# TLE984x register map
Vendor: Infineon Technologies AG; File version: 1.6
CPU: CM0 r0p0, little endian, no MPU, no FPU, 2 interrupt priority bits
Registers are 32-bit, read-write, no defined reset value unless marked. A register's access mark holds for its fields unless they carry their own. Offsets are from the block's base; [hi:lo] are bit positions; {n}, {i} and the like mark numbered series; 'fields as' and 'values as' point back to an identical list.

## ADC1
Base 0x40004000
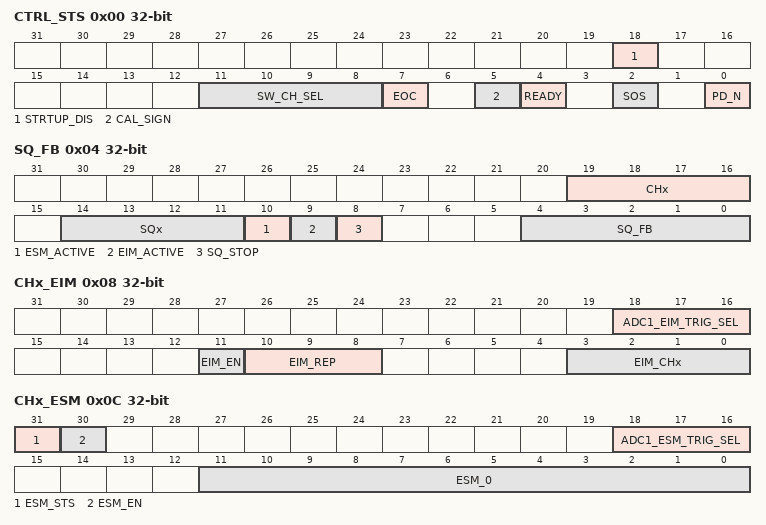
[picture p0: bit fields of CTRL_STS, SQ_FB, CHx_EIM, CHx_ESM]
0x00 CTRL_STS access per field — ADC1 Control and Status Register
  [18] STRTUP_DIS rw — DPP1 Startup Disable
    0=Startup Enable (DPP1 Startup enabled); 1=Startup Disable (DPP1 Startup disable)
  [11:8] SW_CH_SEL rw — Channel for software mode
    {v}=CH{v}_EN (Channel {v} enable) (v=0..12)
  [7] EOC ro — ADC1 End of Conversion (software mode)
    0=Pending (conversion still running); 1=Finished (conversion has finished)
  [5] CAL_SIGN ro — Output of Comparator to Steer Gain / Offset calibration
  [4] READY ro — HVADC Ready bit
    0=Not ready (Module in power down or in init phase); 1=Ready (set automatically 5 ADC clock cycles after module is enabled)
  [2] SOS rw — ADC1 Start of Sampling/Conversion (software mode)
    0=Disable (no conversion is started); 1=Enable (conversion is started)
  [0] PD_N rw — ADC1 Power Down Signal
    0=POWER DOWN (ADC1 is powered down); 1=ACTIVE (ADC1 is switched on)
0x04 SQ_FB ro — Sequencer Feedback Register
  [19:16] CHx — Current ADC1 Channel
    {v}=CH{v} (Channel {v} enable) (v=0..11)
  [14:11] SQx — Current Active ADC1 Sequence
    {v}=SQ{v} (Sequence {v} enable) (v=0..11)
  [10] ESM_ACTIVE — ADC1 ESM active
    0=not active (ESM not active); 1=active (ESM active)
  [9] EIM_ACTIVE — ADC1 EIM active
    0=not active (EIM not active); 1=active (EIM active)
  [8] SQ_STOP — ADC1 Sequencer Stop Signal for DPP
    0=DPP Running (Postprocessing Sequencer in running mode); 1=DPP Stopped (Postprocessing Sequencer stopped / Software Mode entered)
  [4:0] SQ_FB — Current Sequence that caused software mode
    {v}=SQ{v} (Sequence {v} enable) (v=0..11); 26=ESM; 28=SUSPEND_SW (SW Mode per Flag); 29=SUSPEND_DBG (Debug Suspend Mode)
0x08 CHx_EIM — Channel Setting Bits for Exceptional Interrupt Measurement
  [18:16] ADC1_EIM_TRIG_SEL — Trigger selection for exceptional interrupt measurement (EIM)
    0=NONE; 1=COUT63; 2=GPT12_T6OUT; 3=GPT12_T3OUT; 4=T2 (t2_adc_trigger); 5=T21 (t21_adc_trigger)
  [11] EIM_EN — Exceptional interrupt measurement (EIM) Trigger Event enable
    0=DISABLE (start of EIM disabled); 1=ENABLE (start of IEM enabled)
  [10:8] EIM_REP — Repeat count for exceptional interrupt measurement (EIM)
    {v}=Measurements (v=0..7)
  [3:0] EIM_CHx — Channel set for exceptional interrupt measurement (EIM)
    {v}=CH{v}_EN (Channel {v} enable) (v=0..11)
0x0C CHx_ESM — Channel Setting Bits for Exceptional Sequence Measurement
  [31] ESM_STS — Exceptional Sequence Measurement is finished
    0=not active (Exceptional Sequence Measurement not done); 1=done (Exceptional Sequence Measurement done)
  [30] ESM_EN — Enable for Exceptional Sequence Measurement Trigger Event
    0=Disable (start of ESM disabled); 1=Enable (start of ESM enabled)
  [18:16] ADC1_ESM_TRIG_SEL — Trigger selection for exceptional interrupt measurement (ESM)
    values as CHx_EIM.ADC1_EIM_TRIG_SEL
  [11:0] ESM_0 — Channel Sequence for Exceptional Sequence Measurement (ESM)
    1=CH0_EN (Channel 0 enable); 2=CH1_EN (Channel 1 enable); 4=CH2_EN (Channel 2 enable); 8=CH3_EN (Channel 3 enable); 16=CH4_EN (Channel 4 enable); 32=CH5_EN (Channel 5 enable); 64=CH6_EN (Channel 6 enable); 128=CH7_EN (Channel 7 enable); 0x100=CH8_EN (Channel 8 enable); 0x200=CH9_EN (Channel 9 enable); 0x400=CH10_EN (Channel 10 enable); 0x800=CH11_EN (Channel 11 enable)
0x10 MAX_TIME — Maximum Time for Software Mode
  [7:0] MAX_TIME — Maximum Time in Software Mode
    0=min (Software mode is immediately left); 255=max (Software mode is active for 12.75 us)
0x14 CTRL2 — Measurement Unit 1 Control Register 2
  [11:0] CAL_EN — Calibration Enable for Channels 0 to 11
    1=CH0_EN (Channel 0 calibration enable); 2=CH1_EN (Channel 1 calibration enable); 4=CH2_EN (Channel 2 calibration enable); 8=CH3_EN (Channel 3 calibration enable); 16=CH4_EN (Channel 4 calibration enable); 32=CH5_EN (Channel 5 calibration enable); 64=CH6_EN (Channel 6 calibration enable); 128=CH7_EN (Channel 7 calibration enable); 0x100=CH8_EN (Channel 8 calibration enable); 0x200=CH9_EN (Channel 9 calibration enable); 0x400=CH10_EN (Channel 10 calibration enable); 0x800=CH11_EN (Channel 11 calibration enable)
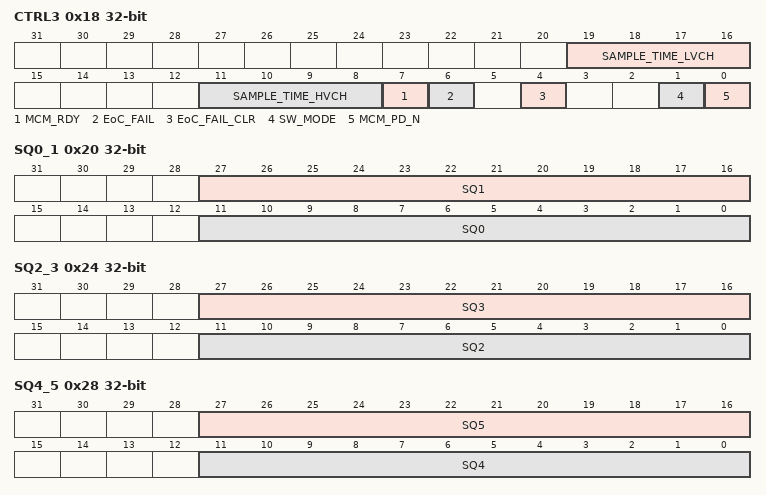
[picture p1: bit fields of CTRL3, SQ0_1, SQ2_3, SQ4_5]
0x18 CTRL3 access per field — Measurement Unit 1 Control Register 3
  [19:16] SAMPLE_TIME_LVCH rw — Sample time of ADC1
    0=MICLK4 (4 ADC1_CLK clock periods(default)); 1=MICLK6 (6 ADC1_CLK clock periods); 2=MICLK8 (8 ADC1_CLK clock periods); 3=MICLK10 (10 ADC1_CLK clock periods); 4=MICLK12 (12 ADC1_CLK clock periods); 5=MICLK14 (14 ADC1_CLK clock periods); 6=MICLK16 (16 ADC1_CLK clock periods); 7=MICLK18 (18 ADC1_CLK clock periods); 8=MICLK20 (20 ADC1_CLK clock periods); 9=MICLK22 (22 ADC1_CLK clock periods)
  [11:8] SAMPLE_TIME_HVCH rw — Sample time of ADC1
    0=MICLK4 (4 ADC1_CLK clock periods); 1=MICLK6 (6 ADC1_CLK clock periods); 2=MICLK8 (8 ADC1_CLK clock periods); 3=MICLK10 (10 ADC1_CLK clock periods); 4=MICLK12 (12 ADC1_CLK clock periods (default)); 5=MICLK14 (14 ADC1_CLK clock periods); 6=MICLK16 (16 ADC1_CLK clock periods); 7=MICLK18 (18 ADC1_CLK clock periods); 8=MICLK20 (20 ADC1_CLK clock periods); 9=MICLK22 (22 ADC1_CLK clock periods)
  [7] MCM_RDY ro — Ready Signal for MCM after Power On or Reset
    0=MCM Not Ready (Measurement Core Module in startup phase); 1=MCM Ready (Measurement Core Module start-up phase finished)
  [6] EoC_FAIL ro — Fail of ADC End of Conversion Signal
    0=ADC EoC available (End of Conversion Signal was sent properly by ADC); 1=ADC EoC not available (End of Conversion Signal was not sent properly by ADC)
  [4] EoC_FAIL_CLR wo — Fail of ADC End of Conversion Signal Clear
    0=ADC EoC Fail not clear (no clear of EoC_FAIL flag); 1=ADC EoC Fail clear (Clear of EoC_FAIL flag)
  [1] SW_MODE rw — SW Mode Enable
    0=Software Mode Disable (Sequencer running); 1=Software Mode Enabled (Sequencer stopped)
  [0] MCM_PD_N rw — Power Down Signal for MCM
    0=MCM Disabled (Measurement Core Module Disabled); 1=MCM Enabled (Measurement Core Module Enabled)
0x1C CTRL5 — Measurement Unit 1 Control Register 5
  [11:0] FILT_OUT_SEL_11_0 — Output Filter Selection for Channels 0 to 11
    0=ADC1 Unfiltered Data can be monitored in the corresponding FILT_OUTx Registers; 1=Channel 0 IIR Data enabled for FILT_OUT0 Register; 2=Channel 1 IIR Data enabled for FILT_OUT1 Register; 4=Channel 2 IIR Data enabled for FILT_OUT2 Register; 8=Channel 3 IIR Data enabled for FILT_OUT3 Register; 16=Channel 4 IIR Data enabled for FILT_OUT4 Register; 32=Channel 5 IIR Data enabled for FILT_OUT5 Register; 64=Channel 6 IIR Data enabled for FILT_OUT6 Register; 128=Channel 7 IIR Data enabled for FILT_OUT7 Register; 0x100=Channel 8 IIR Data enabled for FILT_OUT8 Register; 0x200=Channel 9 IIR Data enabled for FILT_OUT9 Register; 0x400=Channel 10 IIR Data enabled for FILT_OUT10 Register; 0x800=Channel 11 IIR Data enabled for FILT_OUT11 Register; 0xFFF=For Channels 11-0 IIR Data is enabled for FILT_OUTx Registers
0x20 SQ0_1 — Measurement Unit 1 Channel Enable Bits for Cycle 0-1
  [27:16] SQ1 — Sequence 1 channel enable
    values as CHx_ESM.ESM_0
  [11:0] SQ0 — Sequence 0 channel enable
    values as CHx_ESM.ESM_0
0x24 SQ2_3 — Measurement Unit 1 Channel Enable Bits for Cycle 2-3
  [27:16] SQ3 — Sequence 3 channel enable
    values as CHx_ESM.ESM_0
  [11:0] SQ2 — Sequence 2 channel enable
    values as CHx_ESM.ESM_0
0x28 SQ4_5 — Measurement Unit 1 Channel Enable Bits for Cycle 4-5
  [27:16] SQ5 — Sequence 5 channel enable
    values as CHx_ESM.ESM_0
  [11:0] SQ4 — Sequence 4 channel enable
    values as CHx_ESM.ESM_0
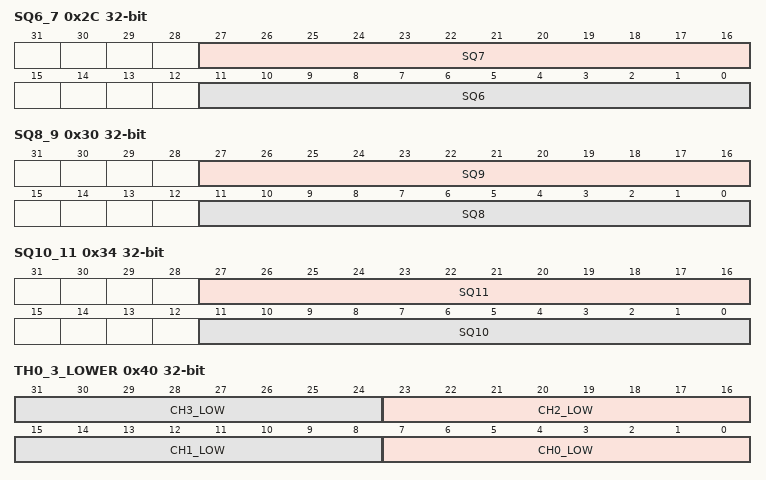
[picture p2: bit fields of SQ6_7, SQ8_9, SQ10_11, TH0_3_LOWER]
0x2C SQ6_7 — Measurement Unit 1 Channel Enable Bits for Cycle 6-7
  [27:16] SQ7 — Sequence 7 channel enable
    values as CHx_ESM.ESM_0
  [11:0] SQ6 — Sequence 6 channel enable
    values as CHx_ESM.ESM_0
0x30 SQ8_9 — Measurement Unit 1 Channel Enable Bits for Cycle 8-9
  [27:16] SQ9 — Sequence 9 channel enable
    values as CHx_ESM.ESM_0
  [11:0] SQ8 — Sequence 8 channel enable
    values as CHx_ESM.ESM_0
0x34 SQ10_11 — Measurement Unit 1 Channel Enable Bits for Cycle 10-11
  [27:16] SQ11 — Sequence 11 channel enable
    values as CHx_ESM.ESM_0
  [11:0] SQ10 — Sequence 10 channel enable
    values as CHx_ESM.ESM_0
0x38 CTRL4 — Measurement Unit 1 Control Register 4
  [3:0] MAX_CALTIME — Maximum ADC Calibration Time
    0=Sequence; 1=Sequences; 2=Sequences; 3=Sequences; 4=Sequence; {v}=Sequences (v=5..15)
0x40 TH0_3_LOWER — Lower Comparator Trigger Level Channel 0-3
  [all] fields
    0=Min. threshold value; 255=Max. threshold value
  [8n+7:8n] CH{n}_LOW (n=0..3) — Channel {n} lower trigger level
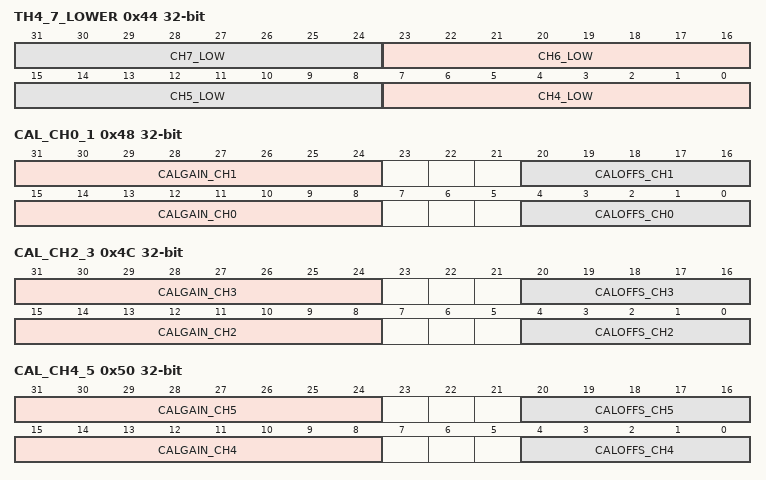
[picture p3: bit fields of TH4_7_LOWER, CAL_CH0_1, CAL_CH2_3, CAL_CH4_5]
0x44 TH4_7_LOWER — Lower Comparator Trigger Level Channel 4-7
  [all] fields
    0=Min. threshold value; 255=Max. threshold value
  [8n-25:8n-32] CH{n}_LOW (n=4..7) — Channel {n} lower trigger level
0x48 CAL_CH0_1 — Calibration for Channel 0 & 1
  [31:24] CALGAIN_CH1 — Gain Calibration for channel 1
  [20:16] CALOFFS_CH1 — Offset Calibration for channel 1
  [15:8] CALGAIN_CH0 — Gain Calibration for channel 0
  [4:0] CALOFFS_CH0 — Offset Calibration for channel 0
0x4C CAL_CH2_3 — Calibration for Channel 2 & 3
  [31:24] CALGAIN_CH3 — Gain Calibration for channel 3
  [20:16] CALOFFS_CH3 — Offset Calibration for channel 3
  [15:8] CALGAIN_CH2 — Gain Calibration for channel 2
  [4:0] CALOFFS_CH2 — Offset Calibration for channel 2
0x50 CAL_CH4_5 — Calibration for Channel 4 & 5
  [31:24] CALGAIN_CH5 — Gain Calibration for channel 5
  [20:16] CALOFFS_CH5 — Offset Calibration for channel 5
  [15:8] CALGAIN_CH4 — Gain Calibration for channel 4
  [4:0] CALOFFS_CH4 — Offset Calibration for channel 4
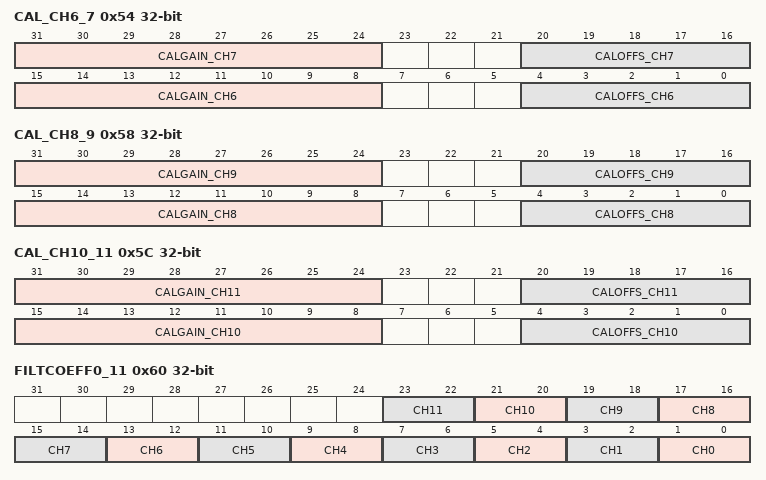
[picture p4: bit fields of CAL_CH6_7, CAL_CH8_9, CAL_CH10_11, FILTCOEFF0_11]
0x54 CAL_CH6_7 — Calibration for Channel 6 & 7
  [31:24] CALGAIN_CH7 — Gain Calibration for channel 7
  [20:16] CALOFFS_CH7 — Offset Calibration for channel 7
  [15:8] CALGAIN_CH6 — Gain Calibration for channel 6
  [4:0] CALOFFS_CH6 — Offset Calibration for channel 6
0x58 CAL_CH8_9 — Calibration for Channel 8 & 9
  [31:24] CALGAIN_CH9 — Gain Calibration for channel 9
  [20:16] CALOFFS_CH9 — Offset Calibration for channel 9
  [15:8] CALGAIN_CH8 — Gain Calibration for channel 8
  [4:0] CALOFFS_CH8 — Offset Calibration for channel 8
0x5C CAL_CH10_11 — Calibration for Channel 10 & 11
  [31:24] CALGAIN_CH11 — Gain Calibration for channel 11
  [20:16] CALOFFS_CH11 — Offset Calibration for channel 11
  [15:8] CALGAIN_CH10 — Gain Calibration for channel 10
  [4:0] CALOFFS_CH10 — Offset Calibration for channel 10
0x60 FILTCOEFF0_11 — Filter Coefficients Measurement Unit Channel 0-11
  [all] fields
    0=1/2 (weight of current sample); 1=1/4 (weight of current sample); 2=1/8 (weight of current sample); 3=1/16 (weight of current sample)
  [2n+1:2n] CH{n} (n=0..11) — Filter Coefficients ADC channel {n}
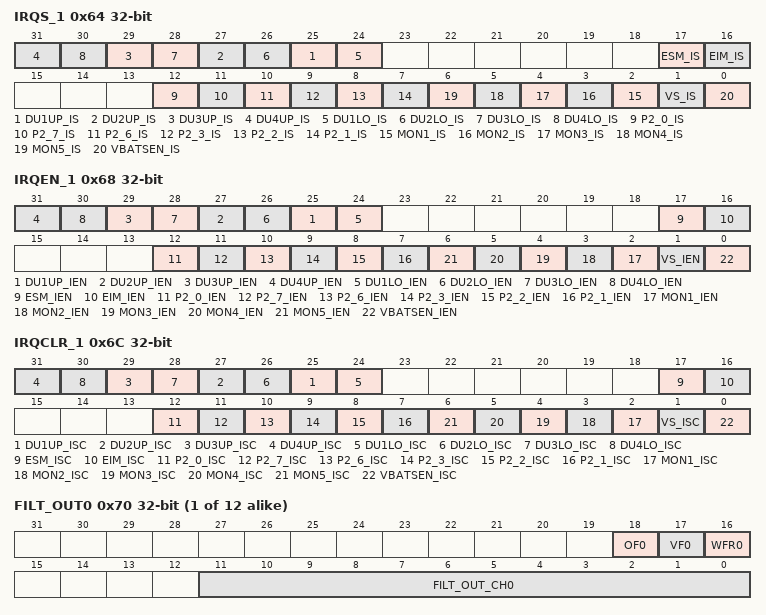
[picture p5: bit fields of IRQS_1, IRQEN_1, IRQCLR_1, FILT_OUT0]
0x64 IRQS_1 — ADC1 Interrupt Status 1 Register
  [2n+23] DU{n}UP_IS (n=1..4) — ADC1 Differential Unit {n} (DU{n}) upper Channel Interrupt Status
    0=INACTIVE (No DU upper Channel Interrupt has occurred); 1=ACTIVE (DU upper Channel Interrupt has occurred)
  [2n+22] DU{n}LO_IS (n=1..4) — ADC1 Differential Unit {n} (DU{n}) lower Channel Interrupt Status
    0=INACTIVE (No DU lower Channel Interrupt has occurred); 1=ACTIVE (DU lower Channel Interrupt has occurred)
  [17] ESM_IS — Exceptional Sequence Measurement (ESM) Status
    0=INACTIVE (No ESM has occurred); 1=ACTIVE (ESM occurred)
  [16] EIM_IS — Exceptional Interrupt Measurement (EIM) Status
    0=INACTIVE (No EIM occurred); 1=ACTIVE (EIM occurred)
  [12] P2_0_IS — ADC1 Channel 12 Interrupt Status
    0=INACTIVE (No Channel 12 Interrupt has occurred); 1=ACTIVE (Channel 12 Interrupt has occurred)
  [11] P2_7_IS — ADC1 Channel 11 Interrupt Status
    0=INACTIVE (No Channel 11 Interrupt has occurred); 1=ACTIVE (Channel 11 Interrupt has occurred)
  [10] P2_6_IS — ADC1 Channel 10 Interrupt Status
    0=INACTIVE (No Channel 10 Interrupt has occurred); 1=ACTIVE (Channel 10 Interrupt has occurred)
  [9] P2_3_IS — ADC1 Channel 9 Interrupt Status
    0=INACTIVE (No Channel 9 Interrupt has occurred); 1=ACTIVE (Channel 9 Interrupt has occurred)
  [8] P2_2_IS — ADC1 Channel 8 Interrupt Status
    0=INACTIVE (No Channel 8 Interrupt has occurred); 1=ACTIVE (Channel 8 Interrupt has occurred)
  [7] P2_1_IS — ADC1 Channel 7 Interrupt Status
    0=INACTIVE (No Channel 7 Interrupt has occurred); 1=ACTIVE (Channel 7 Interrupt has occurred)
  [n+1] MON{n}_IS (n=1..5) — ADC1 Channel {n+1} Interrupt Status
    0=INACTIVE (No Channel {n+1} Interrupt has occurred); 1=ACTIVE (Channel {n+1} Interrupt has occurred)
  [1] VS_IS — ADC1 Channel 0 Interrupt Status
    0=INACTIVE (No Channel 0 Interrupt has occurred); 1=ACTIVE (Channel 0 Interrupt has occurred)
  [0] VBATSEN_IS — ADC1 Channel 1 Interrupt Status
    0=INACTIVE (No Channel 1 Interrupt has occurred); 1=ACTIVE (Channel 1 Interrupt has occurred)
0x68 IRQEN_1 — ADC1 Interrupt Enable 1 Register
  [all] fields
    0=DISABLED (Interrupt disabled); 1=ENABLED (Interrupt enabled)
  [2n+23] DU{n}UP_IEN (n=1..4) — Differential Unit {n} upper Interrupt Enable
  [2n+22] DU{n}LO_IEN (n=1..4) — Differential Unit {n} lower Interrupt Enable
  [17] ESM_IEN — Exceptional Sequence Measurement (ESM) Interrupt Enable
  [16] EIM_IEN — Exceptional Interrupt Measurement (EIM) Interrupt Enable
  [12] P2_0_IEN — ADC1 Port 2.0 Interrupt Enable
  [11] P2_7_IEN — ADC1 Port 2.7 Interrupt Enable
  [10] P2_6_IEN — ADC1 Port 2.6 Interrupt Enable
  [9] P2_3_IEN — ADC1 Port 2.3 Interrupt Enable
  [8] P2_2_IEN — ADC1 Port 2.2 Interrupt Enable
  [7] P2_1_IEN — ADC1 Port 2.1 Interrupt Enable
  [n+1] MON{n}_IEN (n=1..5) — ADC1 MON {n} Interrupt Enable
  [1] VS_IEN — ADC1 VS Interrupt Enable
  [0] VBATSEN_IEN — ADC1 VBAT_SENSE Interrupt Enable
0x6C IRQCLR_1 wo — ADC1 Interrupt Status Clear 1 Register
  [2n+23] DU{n}UP_ISC (n=1..4) — Differential Unit {n} lower Interrupt Status Clear
    0=INACTIVE (interrupt status is not cleared); 1=ACTIVE (interrupt status is cleared)
  [2n+22] DU{n}LO_ISC (n=1..4) — Differential Unit {n} lower Interrupt Status Clear
    values as DU1UP_ISC
  [17] ESM_ISC — Exceptional Sequence Measurement (ESM) Status Clear
    0=INACTIVE (No ESM has cleared); 1=ACTIVE (ESM cleared)
  [16] EIM_ISC — Exceptional Interrupt Measurement (EIM) Status Clear
    0=INACTIVE (No EIM cleared); 1=ACTIVE (EIM cleared)
  [12] P2_0_ISC — ADC1 Port 2.0 Interrupt Status Clear
    values as DU1UP_ISC
  [11] P2_7_ISC — ADC1 Port 2.7 Interrupt Status Clear
    values as DU1UP_ISC
  [10] P2_6_ISC — ADC1 Port 2.6 Interrupt Status Clear
    values as DU1UP_ISC
  [9] P2_3_ISC — ADC1 Port 2.3 Interrupt Status Clear
    values as DU1UP_ISC
  [8] P2_2_ISC — ADC1 Port 2.2 Interrupt Status Clear
    values as DU1UP_ISC
  [7] P2_1_ISC — ADC1 Port 2.1 Interrupt Status Clear
    values as DU1UP_ISC
  [n+1] MON{n}_ISC (n=1..5) — ADC1 MON {n} Interrupt Status Clear
    values as DU1UP_ISC
  [1] VS_ISC — ADC1 VS Interrupt Status Clear
    values as DU1UP_ISC
  [0] VBATSEN_ISC — ADC1 VBAT_SENSE Interrupt Status Clear
    values as DU1UP_ISC
{0x70+4i} FILT_OUT{i} access per field (i=0..11) — ADC1 or Filter Output Channel {i}
  [18] OF{i} ro — Overrun Flag
    0=NO OVERRUN (Result register not overwritten); 1=OVERRUN (Result register overwritten)
  [17] VF{i} ro — Valid Flag
    0=NOT VALID (No new valid data available); 1=VALID (Result register contains valid data and has not yet been read)
  [16] WFR{i} rw — Wait for Read Mode
    0=DISABLE (overwrite mode); 1=ENABLE (wait for read mode enabled)
  [11:0] FILT_OUT_CH{i} ro — ADC or filter output value channel {i}
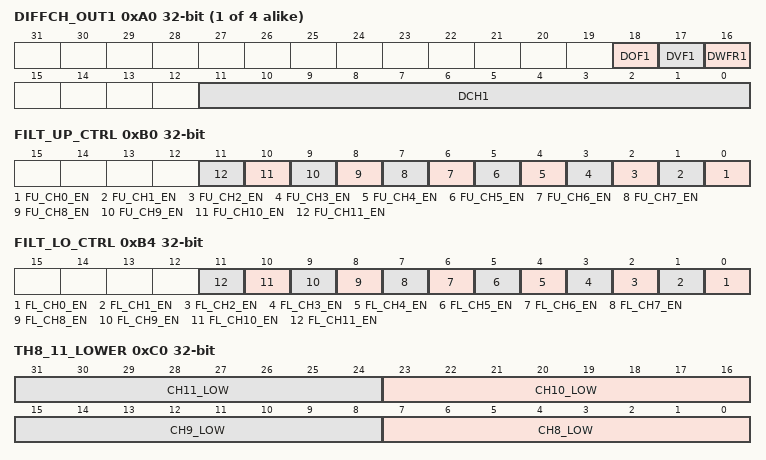
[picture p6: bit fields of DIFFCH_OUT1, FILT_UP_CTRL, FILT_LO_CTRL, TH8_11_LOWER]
{0x9C+4i} DIFFCH_OUT{i} access per field (i=1..4) — ADC1 Differential Channel Output {i}
  [18] DOF{i} ro — Overrun Flag
    values as FILT_OUT0.OF{i}
  [17] DVF{i} ro — Valid Flag
    values as FILT_OUT0.VF{i}
  [16] DWFR{i} rw — Wait for Read Mode
    values as FILT_OUT0.WFR{i}
  [11:0] DCH{i} ro — ADC differential output value {i}
0xB0 FILT_UP_CTRL — Upper Threshold Filter Enable
  [all] fields
    0=disable; 1=enable
  [n] FU_CH{n}_EN (n=0..11) — Upper threshold IIR filter enable Channel {n}
0xB4 FILT_LO_CTRL — Lower Threshold Filter Enable
  [all] fields
    0=disable; 1=enable
  [n] FL_CH{n}_EN (n=0..11) — Lower threshold IIR filter enable Channel {n}
0xC0 TH8_11_LOWER — Lower Comparator Trigger Level Channel 8-11
  [all] fields
    0=Min. threshold value; 255=Max. threshold value
  [8n-57:8n-64] CH{n}_LOW (n=8..11) — Channel {n} lower trigger level
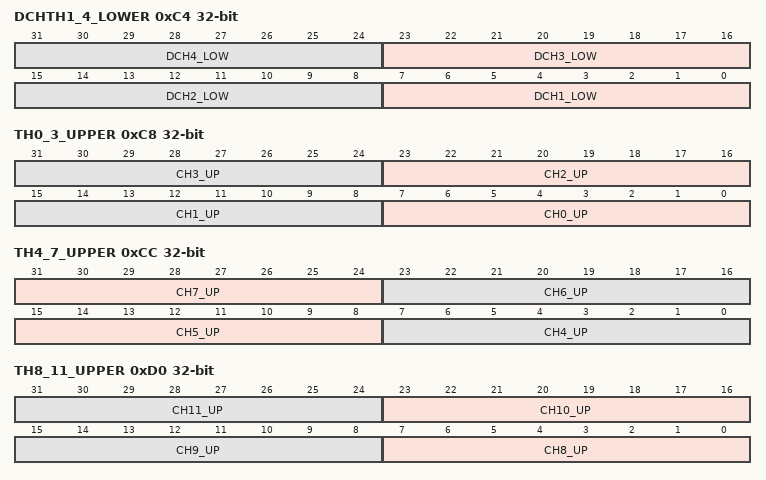
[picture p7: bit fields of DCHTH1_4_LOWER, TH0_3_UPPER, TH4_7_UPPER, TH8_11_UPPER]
0xC4 DCHTH1_4_LOWER — Lower Comparator Trigger Level Differential Channel 1-4
  [all] fields
    0=Min. threshold value; 255=Max. threshold value
  [8n-1:8n-8] DCH{n}_LOW (n=1..4) — Differential Channel {n} lower trigger level
0xC8 TH0_3_UPPER — Upper Comparator Trigger Level Channel 0-3
  [all] fields
    0=min. threshold value = 0; 255=max. threshold value = 255
  [8n+7:8n] CH{n}_UP (n=0..3) — Channel {n} upper trigger level
0xCC TH4_7_UPPER — Upper Comparator Trigger Level Channel 4-7
  [all] fields
    0=min. threshold value = 0; 255=max. threshold value = 255
  [31:24] CH7_UP — Channel 7 upper trigger level
  [23:16] CH6_UP — Channel 6upper trigger level
  [15:8] CH5_UP — Channel 5 upper trigger level
  [7:0] CH4_UP — Channel 4 upper trigger level
0xD0 TH8_11_UPPER — Upper Comparator Trigger Level Channel 8-11
  [all] fields
    0=min. threshold value = 0; 255=max. threshold value = 255
  [8n-57:8n-64] CH{n}_UP (n=8..11) — Channel {n} upper trigger level
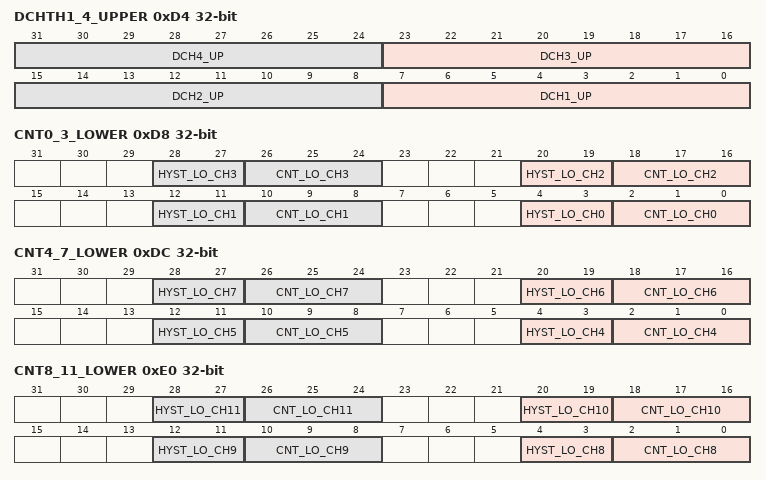
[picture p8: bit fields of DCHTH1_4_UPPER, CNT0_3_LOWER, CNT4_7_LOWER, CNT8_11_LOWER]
0xD4 DCHTH1_4_UPPER — Upper Comparator Trigger Level Differential Channel 1-4
  [all] fields
    0=min. threshold value = 0; 255=max. threshold value = 255
  [8n-1:8n-8] DCH{n}_UP (n=1..4) — Differential Channel {n} upper trigger level
0xD8 CNT0_3_LOWER — Lower Counter Trigger Level Channel 0-3
  [8n+4:8n+3] HYST_LO_CH{n} (n=0..3) — Channel {n} lower hysteresis
    0=HYSTOFF (hysteresis switched off); 1=HYST4 (hysteresis = 4); 2=HYST8 (hysteresis = 8); 3=HYST16 (hysteresis = 16)
  [8n+2:8n] CNT_LO_CH{n} (n=0..3) — Lower timer trigger threshold channel {n}
    0=1 measurement; 1=2 measurements; 2=4 measurements; 3=8 measurements; 4=16 measurements; 5=32 measurements; 6=63 measurements; 7=63 measurements
0xDC CNT4_7_LOWER — Lower Counter Trigger Level Channel 4-7
  [8n-28:8n-29] HYST_LO_CH{n} (n=4..7) — Channel {n} lower hysteresis
    values as CNT0_3_LOWER.HYST_LO_CH0
  [8n-30:8n-32] CNT_LO_CH{n} (n=4..7) — Lower timer trigger threshold channel {n}
    values as CNT0_3_LOWER.CNT_LO_CH0
0xE0 CNT8_11_LOWER — Lower Counter Trigger Level Channel 8-11
  [8n-60:8n-61] HYST_LO_CH{n} (n=8..11) — Channel {n} lower hysteresis
    values as CNT0_3_LOWER.HYST_LO_CH0
  [8n-62:8n-64] CNT_LO_CH{n} (n=8..11) — Lower timer trigger threshold channel {n}
    values as CNT0_3_LOWER.CNT_LO_CH0
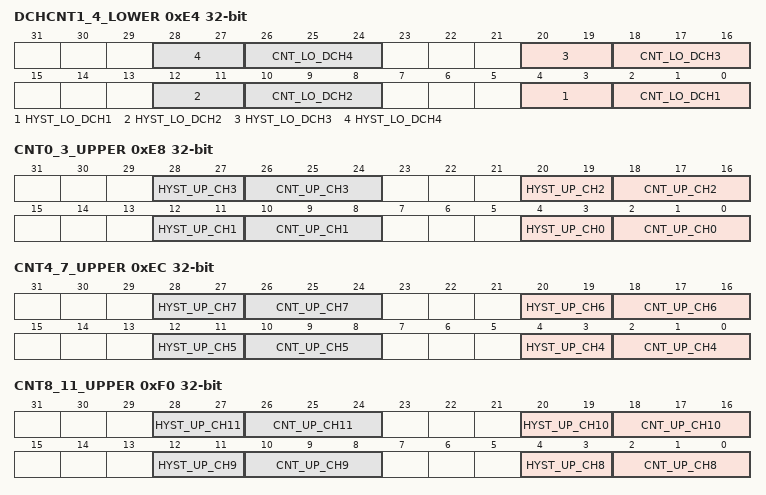
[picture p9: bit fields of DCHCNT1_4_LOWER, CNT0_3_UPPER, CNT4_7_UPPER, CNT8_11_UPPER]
0xE4 DCHCNT1_4_LOWER — Lower Counter Trigger Level Differential Channel 1-4
  [8n-4:8n-5] HYST_LO_DCH{n} (n=1..4) — Differential Channel {n} lower hysteresis
    values as CNT0_3_LOWER.HYST_LO_CH0
  [8n-6:8n-8] CNT_LO_DCH{n} (n=1..4) — Lower timer trigger threshold differential channel {n}
    values as CNT0_3_LOWER.CNT_LO_CH0
0xE8 CNT0_3_UPPER — Upper Counter Trigger Level Channel 0-3
  [8n+4:8n+3] HYST_UP_CH{n} (n=0..3) — Channel {n} upper hysteresis
    values as CNT0_3_LOWER.HYST_LO_CH0
  [8n+2:8n] CNT_UP_CH{n} (n=0..3) — Upper timer trigger threshold channel {n}
    values as CNT0_3_LOWER.CNT_LO_CH0
0xEC CNT4_7_UPPER — Upper Counter Trigger Level Channel 4-7
  [8n-28:8n-29] HYST_UP_CH{n} (n=4..7) — Channel {n} upper hysteresis
    values as CNT0_3_LOWER.HYST_LO_CH0
  [8n-30:8n-32] CNT_UP_CH{n} (n=4..7) — Upper timer trigger threshold channel {n}
    values as CNT0_3_LOWER.CNT_LO_CH0
0xF0 CNT8_11_UPPER — Upper Counter Trigger Level Channel 8-11
  [8n-60:8n-61] HYST_UP_CH{n} (n=8..11) — Channel {n} upper hysteresis
    values as CNT0_3_LOWER.HYST_LO_CH0
  [8n-62:8n-64] CNT_UP_CH{n} (n=8..11) — Upper timer trigger threshold channel {n}
    values as CNT0_3_LOWER.CNT_LO_CH0
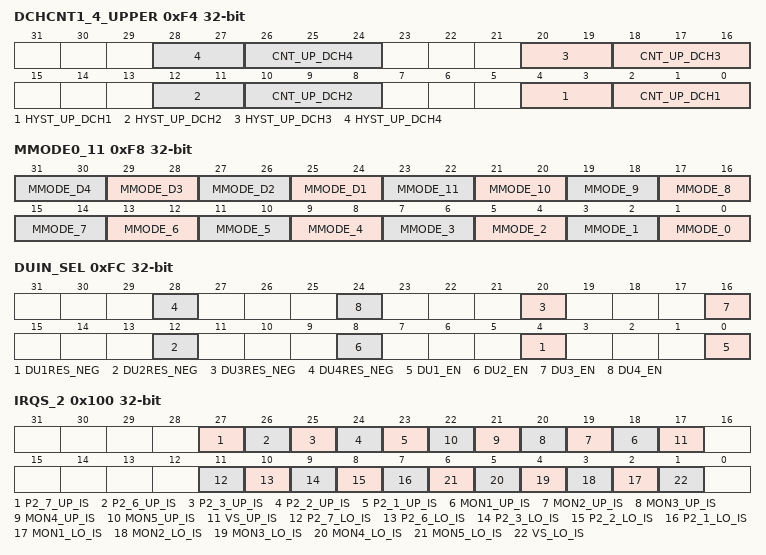
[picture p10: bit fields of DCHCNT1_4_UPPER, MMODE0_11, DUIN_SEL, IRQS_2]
0xF4 DCHCNT1_4_UPPER — Upper Counter Trigger Level Differential Channel 1-4
  [8n-4:8n-5] HYST_UP_DCH{n} (n=1..4) — Differential Channel {n} upper hysteresis
    values as CNT0_3_LOWER.HYST_LO_CH0
  [8n-6:8n-8] CNT_UP_DCH{n} (n=1..4) — Upper timer trigger threshold differential channel {n}
    0=1 measurement; 1=2 measurements; 2=4 measurements; 3=8 measurements; {v}=15 measurements (v=4..7)
0xF8 MMODE0_11 — Overvoltage Measurement Mode of Ch 0-11
  [all] fields
    0=MMODE0 (upper & lower voltage/limit measurement); 1=MMODEUV (undervoltage/-limit measurement); 2=MMODEOV (overvoltage/-limit measurement)
  [2n+23:2n+22] MMODE_D{n} (n=1..4) — Measurement mode Differential Channel {n}
  [2n+1:2n] MMODE_{n} (n=0..11) — Measurement mode Channel {n}
0xFC DUIN_SEL access per field — Measurement Unit 1 - Differential Unit Input Selection Register
  [8n-4] DU{n}RES_NEG ro (n=1..4) — Differential Unit {n} result negative
    0=DU{n} Result positive (Differential Unit {n} result positive after calculation); 1=DU{n} Result negative (Differential Unit {n} result negative after calculation)
  [8n-8] DU{n}_EN rw (n=1..4) — Differential Unit {n} enable
    0=DU{n} disable (Differential Unit {n} is disabled); 1=DU{n} enable (Differential Unit {n} is enabled)
0x100 IRQS_2 — ADC1 Interrupt Status 2 Register
  [all] fields
    0=INACTIVE (no interrupt has occurred); 1=ACTIVE (interrupt has occurred)
  [27] P2_7_UP_IS — ADC1 Port 2.7 Upper Threshold Interrupt Status
  [26] P2_6_UP_IS — ADC1 Port 2.6 Upper Threshold Interrupt Status
  [25] P2_3_UP_IS — ADC1 Port 2.3 Upper Threshold Interrupt Status
  [24] P2_2_UP_IS — ADC1 Port 2.2 Upper Threshold Interrupt Status
  [23] P2_1_UP_IS — ADC1 Port 2.1 Upper Threshold Interrupt Status
  [n+17] MON{n}_UP_IS (n=1..5) — ADC1 MON {n} Upper Threshold Interrupt Status
  [17] VS_UP_IS — ADC1 VS Upper Threshold Interrupt Status
  [11] P2_7_LO_IS — ADC1 Port 2.7 Lower Threshold Interrupt Status
  [10] P2_6_LO_IS — ADC1 Port 2.6 Lower Threshold Interrupt Status
  [9] P2_3_LO_IS — ADC1 Port 2.3 Lower Threshold Interrupt Status
  [8] P2_2_LO_IS — ADC1 Port 2.2 Lower Threshold Interrupt Status
  [7] P2_1_LO_IS — ADC1 Port 2.1 Lower Threshold Interrupt Status
  [n+1] MON{n}_LO_IS (n=1..5) — ADC1 MON {n} Lower Threshold Interrupt Status
  [1] VS_LO_IS — ADC1 VS Lower Threshold Interrupt Status
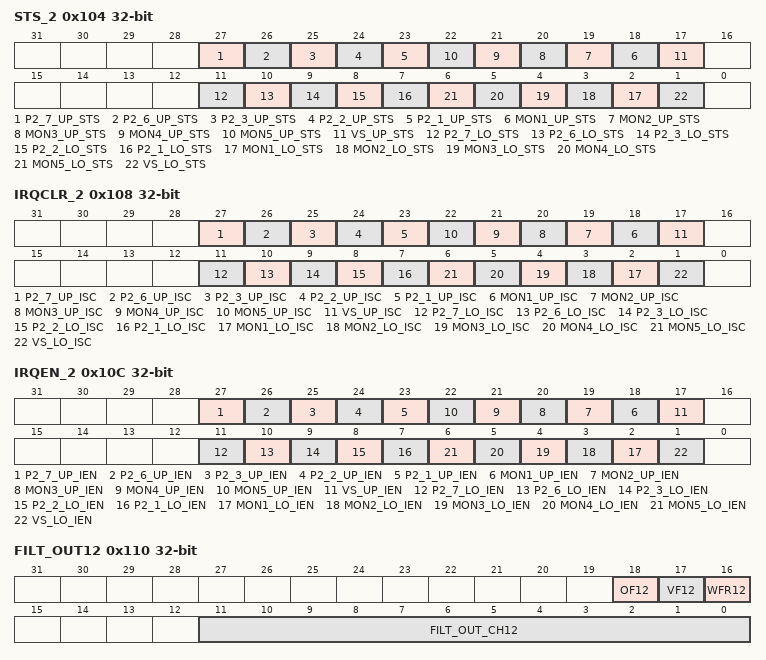
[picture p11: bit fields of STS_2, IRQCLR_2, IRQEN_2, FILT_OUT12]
0x104 STS_2 ro — ADC1 Status 2 Register
  [all] fields
    0=Below limit (Status below upper threshold); 1=Above limit (Upper threshold exceeded)
  [27] P2_7_UP_STS — ADC1 Port 2.7 Upper Threshold Status
  [26] P2_6_UP_STS — ADC1 Port 2.6 Upper Threshold Status
  [25] P2_3_UP_STS — ADC1 Port 2.3 Upper Threshold Status
  [24] P2_2_UP_STS — ADC1 Port 2.2 Upper Threshold Status
  [23] P2_1_UP_STS — ADC1 Port 2.1 Upper Threshold Status
  [n+17] MON{n}_UP_STS (n=1..5) — ADC1 MON {n} Upper Threshold Status
  [17] VS_UP_STS — ADC1 VS Upper Threshold Status
  [11] P2_7_LO_STS — ADC1 Port 2.7 Lower Threshold Status
  [10] P2_6_LO_STS — ADC1 Port 2.6 Lower Threshold Status
  [9] P2_3_LO_STS — ADC1 Port 2.3 Lower Threshold Status
  [8] P2_2_LO_STS — ADC1 Port 2.2 Lower Threshold Status
  [7] P2_1_LO_STS — ADC1 Port 2.1 Lower Threshold Status
  [n+1] MON{n}_LO_STS (n=1..5) — ADC1 MON {n} Lower Threshold Status
  [1] VS_LO_STS — ADC1 VS Lower Threshold Status
0x108 IRQCLR_2 wo — ADC1 Interrupt Status Clear 2 Register
  [all] fields
    values as IRQCLR_1.DU1UP_ISC
  [27] P2_7_UP_ISC — ADC1 Port 2.7 Upper Threshold Interrupt Status Clear
  [26] P2_6_UP_ISC — ADC1 Port 2.6 Upper Threshold Interrupt Status Clear
  [25] P2_3_UP_ISC — ADC1 Port 2.3 Upper Threshold Interrupt Status Clear
  [24] P2_2_UP_ISC — ADC1 Port 2.2 Upper Threshold Interrupt Status Clear
  [23] P2_1_UP_ISC — ADC1 Port 2.1 Upper Threshold Interrupt Status Clear
  [n+17] MON{n}_UP_ISC (n=1..5) — ADC1 MON {n} Upper Threshold Interrupt Status Clear
  [17] VS_UP_ISC — ADC1 VS Upper Threshold Interrupt Status Clear
  [11] P2_7_LO_ISC — ADC1 Port 2.7 Lower Threshold Interrupt Status Clear
  [10] P2_6_LO_ISC — ADC1 Port 2.6 Lower Threshold Interrupt Status Clear
  [9] P2_3_LO_ISC — ADC1 Port 2.3 Lower Threshold Interrupt Status Clear
  [8] P2_2_LO_ISC — ADC1 Port 2.2 Lower Threshold Interrupt Status Clear
  [7] P2_1_LO_ISC — ADC1 Port 2.1 Lower Threshold Interrupt Status Clear
  [n+1] MON{n}_LO_ISC (n=1..5) — ADC1 MON {n} Lower Threshold Interrupt Status Clear
  [1] VS_LO_ISC — ADC1 VS Lower Threshold Interrupt Status Clear
0x10C IRQEN_2 — ADC1 Interrupt Enable 2 Register
  [all] fields
    values as the fields of IRQEN_1
  [27] P2_7_UP_IEN — ADC1 Port 2.7 Upper Threshold Interrupt Enable
  [26] P2_6_UP_IEN — ADC1 Port 2.6 Upper Threshold Interrupt Enable
  [25] P2_3_UP_IEN — ADC1 Port 2.3 Upper Threshold Interrupt Enable
  [24] P2_2_UP_IEN — ADC1 Port 2.2 Upper Threshold Interrupt Enable
  [23] P2_1_UP_IEN — ADC1 Port 2.1 Upper Threshold Interrupt Enable
  [n+17] MON{n}_UP_IEN (n=1..5) — ADC1 MON {n} Upper Threshold Interrupt Enable
  [17] VS_UP_IEN — ADC1 VS Upper Threshold Interrupt Enable
  [11] P2_7_LO_IEN — ADC1 Port 2.7 Lower Threshold Interrupt Enable
  [10] P2_6_LO_IEN — ADC1 Port 2.6 Lower Threshold Interrupt Enable
  [9] P2_3_LO_IEN — ADC1 Port 2.3 Lower Threshold Interrupt Enable
  [8] P2_2_LO_IEN — ADC1 Port 2.2 Lower Threshold Interrupt Enable
  [7] P2_1_LO_IEN — ADC1 Port 2.1 Lower Threshold Interrupt Enable
  [n+1] MON{n}_LO_IEN (n=1..5) — ADC1 MON {n} Lower Threshold Interrupt Enable
  [1] VS_LO_IEN — ADC1 VS Lower Threshold Interrupt Enable
0x110 FILT_OUT12 access per field — ADC1 or Filter Output Channel 12
  [18] OF12 ro — Overrun Flag
    values as FILT_OUT0.OF{i}
  [17] VF12 ro — Valid Flag
    values as FILT_OUT0.VF{i}
  [16] WFR12 rw — Wait for Read Mode
    values as FILT_OUT0.WFR{i}
  [11:0] FILT_OUT_CH12 ro — ADC or filter output value channel 12
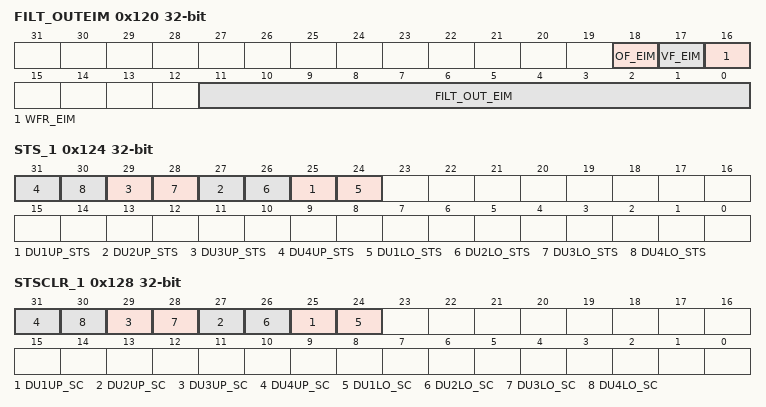
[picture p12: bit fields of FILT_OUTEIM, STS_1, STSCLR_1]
0x120 FILT_OUTEIM access per field — ADC1 or Filter Output of EIM
  [18] OF_EIM ro — Overrun Flag
    values as FILT_OUT0.OF{i}
  [17] VF_EIM ro — Valid Flag
    values as FILT_OUT0.VF{i}
  [16] WFR_EIM rw — Wait for Read Mode
    values as FILT_OUT0.WFR{i}
  [11:0] FILT_OUT_EIM ro — ADC or filter output value for last EIM measurement
0x124 STS_1 — ADC1 Status 1 Register
  [2n+23] DU{n}UP_STS (n=1..4) — ADC1 Differential Unit {n} (DU{n}) upper Channel Status
    0=INACTIVE (No DU upper Channel Status has occurred); 1=ACTIVE (DU upper Channel Status has occurred)
  [2n+22] DU{n}LO_STS (n=1..4) — ADC1 Differential Unit {n} (DU{n}) lower Channel Status
    0=INACTIVE (No DU lower Channel Status has occurred); 1=ACTIVE (DU lower Channel Status has occurred)
0x128 STSCLR_1 wo — ADC1 Status Clear 1 Register
  [2n+23] DU{n}UP_SC (n=1..4) — ADC1 Differential Unit {n} (DU{n}) upper Channel Status Clear
    values as STS_1.DU1UP_STS
  [2n+22] DU{n}LO_SC (n=1..4) — ADC1 Differential Unit {n} (DU{n}) lower Channel Status Clear
    values as STS_1.DU1LO_STS
